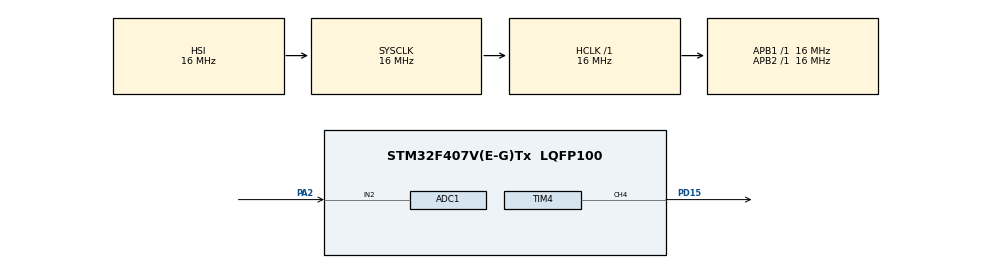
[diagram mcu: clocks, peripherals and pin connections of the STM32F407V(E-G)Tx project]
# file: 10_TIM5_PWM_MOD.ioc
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ADC1.Channel-0\#ChannelRegularConversion=ADC_CHANNEL_2
ADC1.ContinuousConvMode=ENABLE
ADC1.DMAContinuousRequests=ENABLE
ADC1.NbrOfConversionFlag=1
ADC1.Rank-0\#ChannelRegularConversion=1
ADC1.SamplingTime-0\#ChannelRegularConversion=ADC_SAMPLETIME_144CYCLES
ADC1.ScanConvMode=ENABLE
ADC1.master=1
Dma.ADC1.0.Direction=DMA_PERIPH_TO_MEMORY
Dma.ADC1.0.FIFOMode=DMA_FIFOMODE_DISABLE
Dma.ADC1.0.Instance=DMA2_Stream0
Dma.ADC1.0.MemDataAlignment=DMA_MDATAALIGN_HALFWORD
Dma.ADC1.0.MemInc=DMA_MINC_ENABLE
Dma.ADC1.0.Mode=DMA_CIRCULAR
Dma.ADC1.0.PeriphDataAlignment=DMA_PDATAALIGN_HALFWORD
Dma.ADC1.0.PeriphInc=DMA_PINC_DISABLE
Dma.ADC1.0.Priority=DMA_PRIORITY_LOW
Dma.Request0=ADC1
Mcu.Family=STM32F4
Mcu.Name=STM32F407V(E-G)Tx
Mcu.Package=LQFP100
NVIC.DMA2_Stream0_IRQn=true\:0\:0\:false\:false\:true\:false
NVIC.PriorityGroup=NVIC_PRIORITYGROUP_4
PA2.Signal=ADCx_IN2
PD15.Signal=S_TIM4_CH4
ProjectManager.HeapSize=0x200
ProjectManager.StackSize=0x400
ProjectManager.TargetToolchain=MDK-ARM V5
RCC.AHBFreq_Value=16000000
RCC.APB1Freq_Value=16000000
RCC.APB2Freq_Value=16000000
RCC.CortexFreq_Value=16000000
RCC.HSE_VALUE=25000000
RCC.HSI_VALUE=16000000
RCC.LSE_VALUE=32768
RCC.SYSCLKFreq_VALUE=16000000
RCC.VCOOutputFreq_Value=192000000
SH.ADCx_IN2.0=ADC1_IN2,IN2
SH.S_TIM4_CH4.0=TIM4_CH4,PWM Generation4 CH4
TIM4.Channel-PWM\ Generation4\ CH4=TIM_CHANNEL_4
TIM4.OCMode_PWM-PWM\ Generation4\ CH4=TIM_OCMODE_PWM1
TIM4.Period=4095
TIM4.Prescaler=24
VP_TIM4_VS_ClockSourceINT.Mode=Internal
board=10_TIM5_PWM_MOD

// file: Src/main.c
/**
  ******************************************************************************
  * File Name          : main.c
  * Description        : Main program body
  ******************************************************************************
  ** This notice applies to any and all portions of this file
  * that are not between comment pairs USER CODE BEGIN and
  * USER CODE END. Other portions of this file, whether
  * inserted by the user or by software development tools
  * are owned by their respective copyright owners.
  *
  * COPYRIGHT(c) 2018 STMicroelectronics
  *
  * Redistribution and use in source and binary forms, with or without modification,
  * are permitted provided that the following conditions are met:
  *   1. Redistributions of source code must retain the above copyright notice,
  *      this list of conditions and the following disclaimer.
  *   2. Redistributions in binary form must reproduce the above copyright notice,
  *      this list of conditions and the following disclaimer in the documentation
  *      and/or other materials provided with the distribution.
  *   3. Neither the name of STMicroelectronics nor the names of its contributors
  *      may be used to endorse or promote products derived from this software
  *      without specific prior written permission.
  *
  * THIS SOFTWARE IS PROVIDED BY THE COPYRIGHT HOLDERS AND CONTRIBUTORS "AS IS"
  * AND ANY EXPRESS OR IMPLIED WARRANTIES, INCLUDING, BUT NOT LIMITED TO, THE
  * IMPLIED WARRANTIES OF MERCHANTABILITY AND FITNESS FOR A PARTICULAR PURPOSE ARE
  * DISCLAIMED. IN NO EVENT SHALL THE COPYRIGHT HOLDER OR CONTRIBUTORS BE LIABLE
  * FOR ANY DIRECT, INDIRECT, INCIDENTAL, SPECIAL, EXEMPLARY, OR CONSEQUENTIAL
  * DAMAGES (INCLUDING, BUT NOT LIMITED TO, PROCUREMENT OF SUBSTITUTE GOODS OR
  * SERVICES; LOSS OF USE, DATA, OR PROFITS; OR BUSINESS INTERRUPTION) HOWEVER
  * CAUSED AND ON ANY THEORY OF LIABILITY, WHETHER IN CONTRACT, STRICT LIABILITY,
  * OR TORT (INCLUDING NEGLIGENCE OR OTHERWISE) ARISING IN ANY WAY OUT OF THE USE
  * OF THIS SOFTWARE, EVEN IF ADVISED OF THE POSSIBILITY OF SUCH DAMAGE.
  *
  ******************************************************************************
  */
#include "main.h"
#include "stm32f4xx_hal.h"

/* USER CODE BEGIN Includes */
  uint16_t adc1_data[1],pulse;
// adc den okunacak deger ve pwm degerini degistirmek için  pulse tanimlandi
/* USER CODE END Includes */

ADC_HandleTypeDef hadc1;
DMA_HandleTypeDef hdma_adc1;

TIM_HandleTypeDef htim4;

/* USER CODE BEGIN PV */
/* Private variables ---------------------------------------------------------*/

/* USER CODE END PV */

void SystemClock_Config(void);
static void MX_GPIO_Init(void);
static void MX_DMA_Init(void);
static void MX_ADC1_Init(void);
static void MX_TIM4_Init(void);

void HAL_TIM_MspPostInit(TIM_HandleTypeDef *htim);

/* USER CODE BEGIN PFP */
/* Private function prototypes -----------------------------------------------*/

/* USER CODE END PFP */

int main(void)
{

  /* MCU Configuration----------------------------------------------------------*/

  /* Reset of all peripherals, Initializes the Flash interface and the Systick. */
  HAL_Init();

  /* Configure the system clock */
  SystemClock_Config();

  /* Initialize all configured peripherals */
  MX_GPIO_Init();
  MX_DMA_Init();
  MX_ADC1_Init();
  MX_TIM4_Init();

  /* USER CODE BEGIN 2 */

	// adc'yi start edelim :
	HAL_ADC_Start_DMA(&hadc1,(uint32_t*)adc1_data,1);
	// 1 deger okunacak dma ile ..
	// pwm start edilmeli:
	HAL_TIM_PWM_Start(&htim4,TIM_CHANNEL_4);
	// hangi timer ve hangi kanal oldugu yazildi...

  /* USER CODE END 2 */

  /* Infinite loop */
  while (1)
  {

		pulse=adc1_data[0];   // dma ile elde edilen dizinin 1. degiskenine ataniyor
		// ve biz de o degeri pulse degerine atadik.....
		HAL_Delay(10); // degerler tam otursun diye geçikme..
		// pwm i ayarla :
		__HAL_TIM_SetCompare(&htim4,TIM_CHANNEL_4,pulse);
		  // set degerimiz pulse dir.. potun degerini pwm e atadik ...
  }

}

/** System Clock Configuration
*/
void SystemClock_Config(void)
{

  RCC_OscInitTypeDef RCC_OscInitStruct;
  RCC_ClkInitTypeDef RCC_ClkInitStruct;

    /**Configure the main internal regulator output voltage
    */
  __HAL_RCC_PWR_CLK_ENABLE();

  __HAL_PWR_VOLTAGESCALING_CONFIG(PWR_REGULATOR_VOLTAGE_SCALE1);

    /**Initializes the CPU, AHB and APB busses clocks
    */
  RCC_OscInitStruct.OscillatorType = RCC_OSCILLATORTYPE_HSI;
  RCC_OscInitStruct.HSIState = RCC_HSI_ON;
  RCC_OscInitStruct.HSICalibrationValue = 16;
  RCC_OscInitStruct.PLL.PLLState = RCC_PLL_NONE;
  if (HAL_RCC_OscConfig(&RCC_OscInitStruct) != HAL_OK)
  {
    _Error_Handler(__FILE__, __LINE__);
  }

    /**Initializes the CPU, AHB and APB busses clocks
    */
  RCC_ClkInitStruct.ClockType = RCC_CLOCKTYPE_HCLK|RCC_CLOCKTYPE_SYSCLK
                              |RCC_CLOCKTYPE_PCLK1|RCC_CLOCKTYPE_PCLK2;
  RCC_ClkInitStruct.SYSCLKSource = RCC_SYSCLKSOURCE_HSI;
  RCC_ClkInitStruct.AHBCLKDivider = RCC_SYSCLK_DIV1;
  RCC_ClkInitStruct.APB1CLKDivider = RCC_HCLK_DIV1;
  RCC_ClkInitStruct.APB2CLKDivider = RCC_HCLK_DIV1;

  if (HAL_RCC_ClockConfig(&RCC_ClkInitStruct, FLASH_LATENCY_0) != HAL_OK)
  {
    _Error_Handler(__FILE__, __LINE__);
  }

    /**Configure the Systick interrupt time
    */
  HAL_SYSTICK_Config(HAL_RCC_GetHCLKFreq()/1000);

    /**Configure the Systick
    */
  HAL_SYSTICK_CLKSourceConfig(SYSTICK_CLKSOURCE_HCLK);

  /* SysTick_IRQn interrupt configuration */
  HAL_NVIC_SetPriority(SysTick_IRQn, 0, 0);
}

/* ADC1 init function */
static void MX_ADC1_Init(void)
{

  ADC_ChannelConfTypeDef sConfig;

    /**Configure the global features of the ADC (Clock, Resolution, Data Alignment and number of conversion)
    */
  hadc1.Instance = ADC1;
  hadc1.Init.ClockPrescaler = ADC_CLOCK_SYNC_PCLK_DIV2;
  hadc1.Init.Resolution = ADC_RESOLUTION_12B;
  hadc1.Init.ScanConvMode = ENABLE;
  hadc1.Init.ContinuousConvMode = ENABLE;
  hadc1.Init.DiscontinuousConvMode = DISABLE;
  hadc1.Init.ExternalTrigConvEdge = ADC_EXTERNALTRIGCONVEDGE_NONE;
  hadc1.Init.ExternalTrigConv = ADC_SOFTWARE_START;
  hadc1.Init.DataAlign = ADC_DATAALIGN_RIGHT;
  hadc1.Init.NbrOfConversion = 1;
  hadc1.Init.DMAContinuousRequests = ENABLE;
  hadc1.Init.EOCSelection = ADC_EOC_SINGLE_CONV;
  if (HAL_ADC_Init(&hadc1) != HAL_OK)
  {
    _Error_Handler(__FILE__, __LINE__);
  }

    /**Configure for the selected ADC regular channel its corresponding rank in the sequencer and its sample time.
    */
  sConfig.Channel = ADC_CHANNEL_2;
  sConfig.Rank = 1;
  sConfig.SamplingTime = ADC_SAMPLETIME_144CYCLES;
  if (HAL_ADC_ConfigChannel(&hadc1, &sConfig) != HAL_OK)
  {
    _Error_Handler(__FILE__, __LINE__);
  }

}

/* TIM4 init function */
static void MX_TIM4_Init(void)
{

  TIM_ClockConfigTypeDef sClockSourceConfig;
  TIM_MasterConfigTypeDef sMasterConfig;
  TIM_OC_InitTypeDef sConfigOC;

  htim4.Instance = TIM4;
  htim4.Init.Prescaler = 24;
  htim4.Init.CounterMode = TIM_COUNTERMODE_UP;
  htim4.Init.Period = 4095;
  htim4.Init.ClockDivision = TIM_CLOCKDIVISION_DIV1;
  if (HAL_TIM_Base_Init(&htim4) != HAL_OK)
  {
    _Error_Handler(__FILE__, __LINE__);
  }

  sClockSourceConfig.ClockSource = TIM_CLOCKSOURCE_INTERNAL;
  if (HAL_TIM_ConfigClockSource(&htim4, &sClockSourceConfig) != HAL_OK)
  {
    _Error_Handler(__FILE__, __LINE__);
  }

  if (HAL_TIM_PWM_Init(&htim4) != HAL_OK)
  {
    _Error_Handler(__FILE__, __LINE__);
  }

  sMasterConfig.MasterOutputTrigger = TIM_TRGO_RESET;
  sMasterConfig.MasterSlaveMode = TIM_MASTERSLAVEMODE_DISABLE;
  if (HAL_TIMEx_MasterConfigSynchronization(&htim4, &sMasterConfig) != HAL_OK)
  {
    _Error_Handler(__FILE__, __LINE__);
  }

  sConfigOC.OCMode = TIM_OCMODE_PWM1;
  sConfigOC.Pulse = 0;                                // burda adc den komayipta kendimizde girebiliriz...
  sConfigOC.OCPolarity = TIM_OCPOLARITY_HIGH;
  sConfigOC.OCFastMode = TIM_OCFAST_DISABLE;
  if (HAL_TIM_PWM_ConfigChannel(&htim4, &sConfigOC, TIM_CHANNEL_4) != HAL_OK)
  {
    _Error_Handler(__FILE__, __LINE__);
  }

  HAL_TIM_MspPostInit(&htim4);

}

static void MX_DMA_Init(void)
{
  /* DMA controller clock enable */
  __HAL_RCC_DMA2_CLK_ENABLE();

  /* DMA interrupt init */
  /* DMA2_Stream0_IRQn interrupt configuration */
  HAL_NVIC_SetPriority(DMA2_Stream0_IRQn, 0, 0);
  HAL_NVIC_EnableIRQ(DMA2_Stream0_IRQn);

}

/** Pinout Configuration
*/
static void MX_GPIO_Init(void)
{

  /* GPIO Ports Clock Enable */
  __HAL_RCC_GPIOA_CLK_ENABLE();
  __HAL_RCC_GPIOD_CLK_ENABLE();

}

void _Error_Handler(char * file, int line)
{
  while(1)
  {
  }
}

/************************ (C) COPYRIGHT STMicroelectronics *****END OF FILE****/
